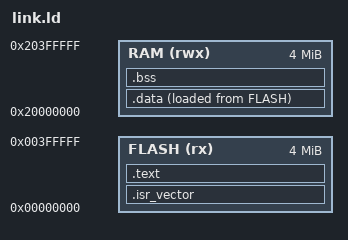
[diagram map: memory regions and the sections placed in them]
/* {{NAME}} memory map (qemu mps2-an385): code at 0, RAM at 0x20000000. Edit ORIGIN/LENGTH for your chip. */
MEMORY
{
  FLASH (rx)  : ORIGIN = 0x00000000, LENGTH = 4M
  RAM   (rwx) : ORIGIN = 0x20000000, LENGTH = 4M
}
ENTRY(Reset_Handler)
_estack = ORIGIN(RAM) + LENGTH(RAM);
SECTIONS
{
  .isr_vector : { KEEP(*(.isr_vector)) } > FLASH
  .text : { *(.text*) *(.rodata*) KEEP(*(.init)) KEEP(*(.fini)) . = ALIGN(4); } > FLASH
  _sidata = LOADADDR(.data);
  .data : { _sdata = .; *(.data*) . = ALIGN(4); _edata = .; } > RAM AT > FLASH
  .bss (NOLOAD) : { _sbss = .; *(.bss*) *(COMMON) . = ALIGN(4); _ebss = .; } > RAM
  end = .;
}
